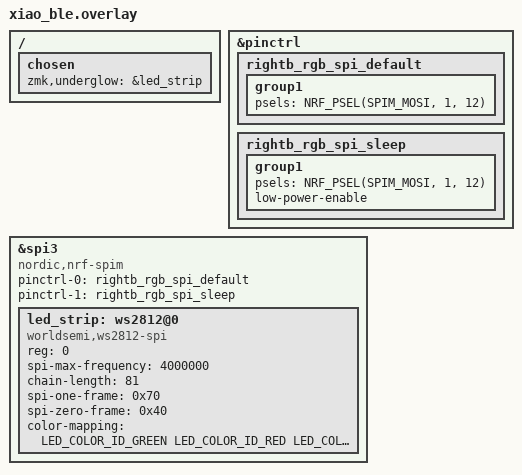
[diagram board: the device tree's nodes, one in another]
#include <dt-bindings/led/led.h>

&pinctrl {
    rightb_rgb_spi_default: rightb_rgb_spi_default {
        group1 {
            psels = <NRF_PSEL(SPIM_MOSI, 1, 12)>;
        };
    };

    rightb_rgb_spi_sleep: rightb_rgb_spi_sleep {
        group1 {
            psels = <NRF_PSEL(SPIM_MOSI, 1, 12)>;
            low-power-enable;
        };
    };
};

&spi3 {
    compatible = "nordic,nrf-spim";
    status = "okay";

    pinctrl-0 = <&rightb_rgb_spi_default>;
    pinctrl-1 = <&rightb_rgb_spi_sleep>;
    pinctrl-names = "default", "sleep";

    led_strip: ws2812@0 {
        compatible = "worldsemi,ws2812-spi";

        reg = <0>;
        spi-max-frequency = <4000000>;

        chain-length = <81>;

        spi-one-frame = <0x70>;
        spi-zero-frame = <0x40>;

        color-mapping = <LED_COLOR_ID_GREEN
                         LED_COLOR_ID_RED
                         LED_COLOR_ID_BLUE>;
    };
};

/ {
    chosen {
        zmk,underglow = &led_strip;
    };
};
